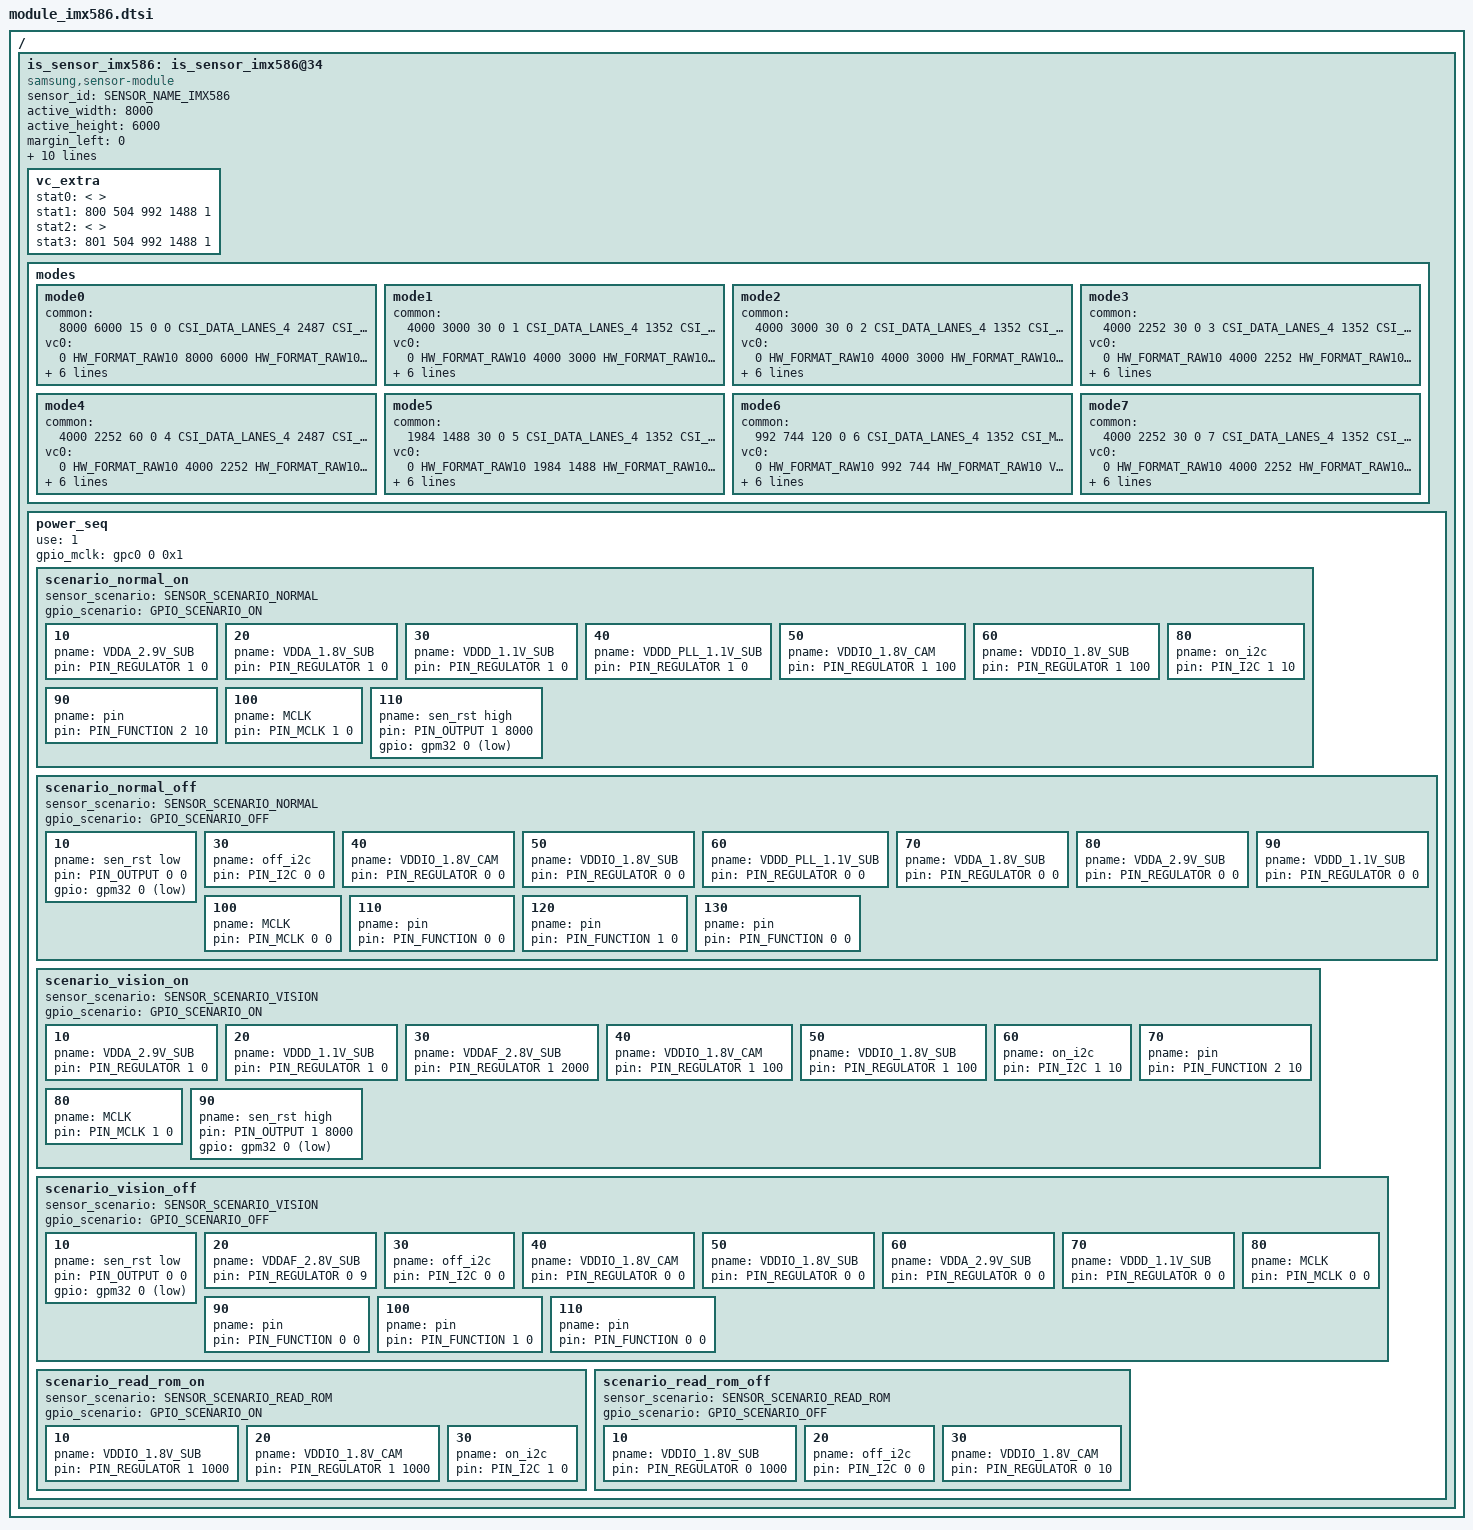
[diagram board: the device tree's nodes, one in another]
/*
 * SAMSUNG EXYNOSxxxx board camera device tree source
 *
 * Copyright (c) 2019 Samsung Electronics Co., Ltd.
 *		http://www.samsung.com
 *
 * This program is free software; you can redistribute it and/or modify
 * it under the terms of the GNU General Public License version 2 as
 * published by the Free Software Foundation.
 */

#include <dt-bindings/camera/exynos_is_dt.h>

/ {
	fragment@camera {
		target-path = "/";
		__overlay__ {
			is_sensor_imx586: is_sensor_imx586@34 {
				compatible = "samsung,sensor-module";

				/* common */
				sensor_id = <SENSOR_NAME_IMX586>;
				active_width = <8000>;
				active_height = <6000>;
				margin_left = <0>;
				margin_right = <0>;
				margin_top = <0>;
				margin_bottom = <0>;
				max_framerate = <120>;
				bitwidth = <10>;
				use_retention_mode = <SENSOR_RETENTION_UNSUPPORTED>;
				sensor_maker = "SONY";
				sensor_name = "IMX586";
				setfile_name = "setfile_imx586.bin";

				status = "okay";

				vc_extra {
					/* ex) statX = <stat_type, sensor_mode, max_width, max_height, max_element> */
					stat0 = </* not avaliable */>;									/* VC_BUF_DATA_TYPE_SENSOR_STAT1 */
					stat1 = </*VC_STAT_TYPE_PDP_1_1_PDAF_STAT0*/ 800 /*VC_SENSOR_MODE_IMX_2X1OCL_2_TAIL*/ 504 992 1488 1>;	/* VC_BUF_DATA_TYPE_GENERAL_STAT1 */
					stat2 = </* not avaliable */>;									/* VC_BUF_DATA_TYPE_SENSOR_STAT2 */
					stat3 = </*VC_STAT_TYPE_PDP_1_1_PDAF_STAT1*/ 801 /*VC_SENSOR_MODE_IMX_2X1OCL_2_TAIL*/ 504 992 1488 1>;	/* VC_BUF_DATA_TYPE_GENERAL_STAT2 */
				};

				/* sensor modes */
				modes {
					/* common = <width, height, fps, settle, mode, lane, speed, interleave, lrte, pd_mode> */
					/* vcX = <map, hwformat, width, height, hwformat, type, width, height> */

					mode0 {
						common = <8000 6000 15 0 0 CSI_DATA_LANES_4 2487 CSI_MODE_VC_ONLY LRTE_DISABLE PD_NONE EX_NONE>;
						vc0 = </* in */ 0 HW_FORMAT_RAW10 8000 6000	/* out */ HW_FORMAT_RAW10 VC_NOTHING 8000 6000>;
						vc1 = </* in */ 1 HW_FORMAT_RAW10 496 2976	/* out */ HW_FORMAT_RAW10 VC_NOTHING 0 0>;
						vc2 = </* in */ 2 HW_FORMAT_UNKNOWN 0 0		/* out */ HW_FORMAT_UNKNOWN VC_NOTHING 0 0>;
						vc3 = </* in */ 3 HW_FORMAT_UNKNOWN 0 0		/* out */ HW_FORMAT_UNKNOWN VC_NOTHING 0 0>;
					};
					mode1 {
						common = <4000 3000 30 0 1 CSI_DATA_LANES_4 1352 CSI_MODE_VC_ONLY LRTE_DISABLE PD_MSPD_TAIL EX_NONE>;
						vc0 = </* in */ 0 HW_FORMAT_RAW10 4000 3000	/* out */ HW_FORMAT_RAW10 VC_NOTHING 4000 3000>;
						vc1 = </* in */ 1 HW_FORMAT_RAW10 992 1488	/* out */ HW_FORMAT_RAW10 VC_TAILPDAF 992 1488>;
						vc2 = </* in */ 2 HW_FORMAT_UNKNOWN 0 0		/* out */ HW_FORMAT_UNKNOWN VC_NOTHING 0 0>;
						vc3 = </* in */ 3 HW_FORMAT_UNKNOWN 0 0		/* out */ HW_FORMAT_UNKNOWN VC_NOTHING 0 0>;
					};
					mode2 {
						common = <4000 3000 30 0 2 CSI_DATA_LANES_4 1352 CSI_MODE_VC_ONLY LRTE_DISABLE PD_NONE EX_LOW_RES_TETRA>;
						vc0 = </* in */ 0 HW_FORMAT_RAW10 4000 3000	/* out */ HW_FORMAT_RAW10 VC_NOTHING 4000 3000>;
						vc1 = </* in */ 1 HW_FORMAT_RAW10 248 1472	/* out */ HW_FORMAT_RAW10 VC_NOTHING 0 0>;
						vc2 = </* in */ 2 HW_FORMAT_UNKNOWN 0 0		/* out */ HW_FORMAT_UNKNOWN VC_NOTHING 0 0>;
						vc3 = </* in */ 3 HW_FORMAT_UNKNOWN 0 0		/* out */ HW_FORMAT_UNKNOWN VC_NOTHING 0 0>;
					};
					mode3 {
						common = <4000 2252 30 0 3 CSI_DATA_LANES_4 1352 CSI_MODE_VC_ONLY LRTE_DISABLE PD_MSPD_TAIL EX_NONE>;
						vc0 = </* in */ 0 HW_FORMAT_RAW10 4000 2252	/* out */ HW_FORMAT_RAW10 VC_NOTHING 4000 2252>;
						vc1 = </* in */ 1 HW_FORMAT_RAW10 992 1120	/* out */ HW_FORMAT_RAW10 VC_TAILPDAF 992 1120>;
						vc2 = </* in */ 2 HW_FORMAT_UNKNOWN 0 0		/* out */ HW_FORMAT_UNKNOWN VC_NOTHING 0 0>;
						vc3 = </* in */ 3 HW_FORMAT_UNKNOWN 0 0		/* out */ HW_FORMAT_UNKNOWN VC_NOTHING 0 0>;
					};
					mode4 {
						common = <4000 2252 60 0 4 CSI_DATA_LANES_4 2487 CSI_MODE_VC_ONLY LRTE_DISABLE PD_MSPD_TAIL EX_NONE>;
						vc0 = </* in */ 0 HW_FORMAT_RAW10 4000 2252	/* out */ HW_FORMAT_RAW10 VC_NOTHING 4000 2252>;
						vc1 = </* in */ 1 HW_FORMAT_RAW10 992 1120	/* out */ HW_FORMAT_RAW10 VC_TAILPDAF 992 1120>;
						vc2 = </* in */ 2 HW_FORMAT_UNKNOWN 0 0		/* out */ HW_FORMAT_UNKNOWN VC_NOTHING 0 0>;
						vc3 = </* in */ 3 HW_FORMAT_UNKNOWN 0 0		/* out */ HW_FORMAT_UNKNOWN VC_NOTHING 0 0>;
					};
					mode5 {
						common = <1984 1488 30 0 5 CSI_DATA_LANES_4 1352 CSI_MODE_VC_ONLY LRTE_DISABLE PD_MSPD_TAIL EX_NONE>;
						vc0 = </* in */ 0 HW_FORMAT_RAW10 1984 1488	/* out */ HW_FORMAT_RAW10 VC_NOTHING 1984 1488>;
						vc1 = </* in */ 1 HW_FORMAT_RAW10 496 736	/* out */ HW_FORMAT_RAW10 VC_TAILPDAF 496 736>;
						vc2 = </* in */ 2 HW_FORMAT_UNKNOWN 0 0		/* out */ HW_FORMAT_UNKNOWN VC_NOTHING 0 0>;
						vc3 = </* in */ 3 HW_FORMAT_UNKNOWN 0 0		/* out */ HW_FORMAT_UNKNOWN VC_NOTHING 0 0>;
					};
					mode6 {
						common = <992 744 120 0 6 CSI_DATA_LANES_4 1352 CSI_MODE_VC_ONLY LRTE_DISABLE PD_NONE>;
						vc0 = </* in */ 0 HW_FORMAT_RAW10 992 744	/* out */ HW_FORMAT_RAW10 VC_NOTHING 992 744>;
						vc1 = </* in */ 1 HW_FORMAT_UNKNOWN 0 0		/* out */ HW_FORMAT_UNKNOWN VC_NOTHING 0 0>;
						vc2 = </* in */ 2 HW_FORMAT_UNKNOWN 0 0		/* out */ HW_FORMAT_UNKNOWN VC_NOTHING 0 0>;
						vc3 = </* in */ 3 HW_FORMAT_UNKNOWN 0 0		/* out */ HW_FORMAT_UNKNOWN VC_NOTHING 0 0>;
					};
					mode7 {
						common = <4000 2252 30 0 7 CSI_DATA_LANES_4 1352 CSI_MODE_VC_ONLY LRTE_DISABLE PD_NONE EX_LOW_RES_TETRA>;
						vc0 = </* in */ 0 HW_FORMAT_RAW10 4000 2252	/* out */ HW_FORMAT_RAW10 VC_NOTHING 4000 2252>;
						vc1 = </* in */ 1 HW_FORMAT_RAW10 248 1120	/* out */ HW_FORMAT_RAW10 VC_NOTHING 0 0>;
						vc2 = </* in */ 2 HW_FORMAT_UNKNOWN 0 0		/* out */ HW_FORMAT_UNKNOWN VC_NOTHING 0 0>;
						vc3 = </* in */ 3 HW_FORMAT_UNKNOWN 0 0		/* out */ HW_FORMAT_UNKNOWN VC_NOTHING 0 0>;
					};
				};

				power_seq {
					use = <1>;
					gpio_mclk = <&gpc0 0 0x1>;

					scenario_normal_on {
						sensor_scenario = <SENSOR_SCENARIO_NORMAL>;
						gpio_scenario = <GPIO_SCENARIO_ON>;

						/* A start node number should be over the 10 for reserved number 0~9. */
						/* pname = "name"; pin = <act value delay voltage>; gpio = <gpx# # 0x1>; */
						10 { pname = "VDDA_2.9V_SUB"; pin = <PIN_REGULATOR 1 0>; };
						20 { pname = "VDDA_1.8V_SUB"; pin = <PIN_REGULATOR 1 0>; };
						30 { pname = "VDDD_1.1V_SUB"; pin = <PIN_REGULATOR 1 0>; };
						40 { pname = "VDDD_PLL_1.1V_SUB"; pin = <PIN_REGULATOR 1 0>; };
						50 { pname = "VDDIO_1.8V_CAM"; pin = <PIN_REGULATOR 1 100>; };
						60 { pname = "VDDIO_1.8V_SUB"; pin = <PIN_REGULATOR 1 100>; };
						80 { pname = "on_i2c"; pin = <PIN_I2C 1 10>; };
						90 { pname = "pin"; pin = <PIN_FUNCTION 2 10>; };
						100 { pname = "MCLK"; pin = <PIN_MCLK 1 0>; };
						110 { pname = "sen_rst high"; pin = <PIN_OUTPUT 1 8000>; gpio = <&gpm32 0 0x1>; };
					};

					scenario_normal_off {
						sensor_scenario = <SENSOR_SCENARIO_NORMAL>;
						gpio_scenario = <GPIO_SCENARIO_OFF>;

						/* A start node number should be over the 10 for reserved number 0~9. */
						/* pname = "name"; pin = <act value delay voltage>; gpio = <gpx# # 0x1>; */
						10 { pname = "sen_rst low"; pin = <PIN_OUTPUT 0 0>; gpio = <&gpm32 0 0x1>; };
						30 { pname = "off_i2c"; pin = <PIN_I2C 0 0>; };
						40 { pname = "VDDIO_1.8V_CAM"; pin = <PIN_REGULATOR 0 0>; };
						50 { pname = "VDDIO_1.8V_SUB"; pin = <PIN_REGULATOR 0 0>; };
						60 { pname = "VDDD_PLL_1.1V_SUB"; pin = <PIN_REGULATOR 0 0>; };
						70 { pname = "VDDA_1.8V_SUB"; pin = <PIN_REGULATOR 0 0>; };
						80 { pname = "VDDA_2.9V_SUB"; pin = <PIN_REGULATOR 0 0>; };
						90 { pname = "VDDD_1.1V_SUB"; pin = <PIN_REGULATOR 0 0>; };
						100 { pname = "MCLK"; pin = <PIN_MCLK 0 0>; };
						110 { pname = "pin"; pin = <PIN_FUNCTION 0 0>; };
						120 { pname = "pin"; pin = <PIN_FUNCTION 1 0>; };
						130 { pname = "pin"; pin = <PIN_FUNCTION 0 0>; };
					};

					scenario_vision_on {
						sensor_scenario = <SENSOR_SCENARIO_VISION>;
						gpio_scenario = <GPIO_SCENARIO_ON>;

						/* A start node number should be over the 10 for reserved number 0~9. */
						/* pname = "name"; pin = <act value delay voltage>; gpio = <gpx# # 0x1>; */
						10 { pname = "VDDA_2.9V_SUB"; pin = <PIN_REGULATOR 1 0>; };
						20 { pname = "VDDD_1.1V_SUB"; pin = <PIN_REGULATOR 1 0>; };
						30 { pname = "VDDAF_2.8V_SUB"; pin = <PIN_REGULATOR 1 2000>; };
						40 { pname = "VDDIO_1.8V_CAM"; pin = <PIN_REGULATOR 1 100>; };
						50 { pname = "VDDIO_1.8V_SUB"; pin = <PIN_REGULATOR 1 100>; };
						60 { pname = "on_i2c"; pin = <PIN_I2C 1 10>; };
						70 { pname = "pin"; pin = <PIN_FUNCTION 2 10>; };
						80 { pname = "MCLK"; pin = <PIN_MCLK 1 0>; };
						90 { pname = "sen_rst high"; pin = <PIN_OUTPUT 1 8000>; gpio = <&gpm32 0 0x1>; };
					};

					scenario_vision_off {
						sensor_scenario = <SENSOR_SCENARIO_VISION>;
						gpio_scenario = <GPIO_SCENARIO_OFF>;

						/* A start node number should be over the 10 for reserved number 0~9. */
						/* pname = "name"; pin = <act value delay voltage>; gpio = <gpx# # 0x1>; */
						10 { pname = "sen_rst low"; pin = <PIN_OUTPUT 0 0>; gpio = <&gpm32 0 0x1>; };
						20 { pname = "VDDAF_2.8V_SUB"; pin = <PIN_REGULATOR 0 9>; };
						30 { pname = "off_i2c"; pin = <PIN_I2C 0 0>; };
						40 { pname = "VDDIO_1.8V_CAM"; pin = <PIN_REGULATOR 0 0>; };
						50 { pname = "VDDIO_1.8V_SUB"; pin = <PIN_REGULATOR 0 0>; };
						60 { pname = "VDDA_2.9V_SUB"; pin = <PIN_REGULATOR 0 0>; };
						70 { pname = "VDDD_1.1V_SUB"; pin = <PIN_REGULATOR 0 0>; };
						80 { pname = "MCLK"; pin = <PIN_MCLK 0 0>; };
						90 { pname = "pin"; pin = <PIN_FUNCTION 0 0>; };
						100 { pname = "pin"; pin = <PIN_FUNCTION 1 0>; };
						110 { pname = "pin"; pin = <PIN_FUNCTION 0 0>; };
					};

					scenario_read_rom_on {
						sensor_scenario = <SENSOR_SCENARIO_READ_ROM>;
						gpio_scenario = <GPIO_SCENARIO_ON>;

						/* A start node number should be over the 10 for reserved number 0~9. */
						/* pname = "name"; pin = <act value delay voltage>; gpio = <gpx# # 0x1>; */
						10 { pname = "VDDIO_1.8V_SUB"; pin = <PIN_REGULATOR 1 1000>; };
						20 { pname = "VDDIO_1.8V_CAM"; pin = <PIN_REGULATOR 1 1000>; };
						30 { pname = "on_i2c"; pin = <PIN_I2C 1 0>; };
					};

					scenario_read_rom_off {
						sensor_scenario = <SENSOR_SCENARIO_READ_ROM>;
						gpio_scenario = <GPIO_SCENARIO_OFF>;

						/* A start node number should be over the 10 for reserved number 0~9. */
						/* pname = "name"; pin = <act value delay voltage>; gpio = <gpx# # 0x1>; */
						10 { pname = "VDDIO_1.8V_SUB"; pin = <PIN_REGULATOR 0 1000>; };
						20 { pname = "off_i2c"; pin = <PIN_I2C 0 0>; };
						30 { pname = "VDDIO_1.8V_CAM"; pin = <PIN_REGULATOR 0 10>; };
					};
				};
			};
		}; /* end of __overlay__ */
	}; /* end of fragment */
}; /* end of root */
